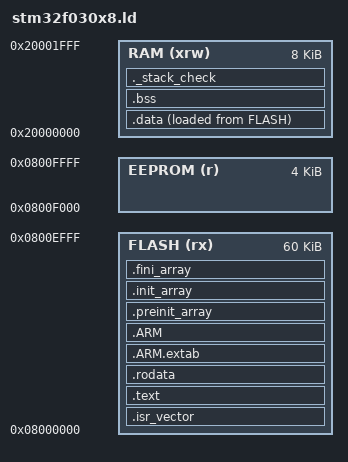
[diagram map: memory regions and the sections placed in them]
/* Linker script for the STM32F030C8 on the BIGTREETECH MMU2-DIP */

ENTRY(Reset_Handler)

/* The last 4 KB of flash hold the emulated EEPROM, see eeprom.cpp */
MEMORY
{
  FLASH (rx)  : ORIGIN = 0x08000000, LENGTH = 60K
  EEPROM (r)  : ORIGIN = 0x0800F000, LENGTH = 4K
  RAM (xrw)   : ORIGIN = 0x20000000, LENGTH = 8K
}

_estack = ORIGIN(RAM) + LENGTH(RAM);
_eeprom_start = ORIGIN(EEPROM);
_eeprom_end = ORIGIN(EEPROM) + LENGTH(EEPROM);

/* Fail the link if this much stack + heap doesn't fit */
_min_stack_size = 0x400;

SECTIONS
{
  .isr_vector :
  {
    . = ALIGN(4);
    KEEP(*(.isr_vector))
    . = ALIGN(4);
  } > FLASH

  .text :
  {
    . = ALIGN(4);
    *(.text)
    *(.text*)
    *(.glue_7)
    *(.glue_7t)
    *(.eh_frame)
    KEEP(*(.init))
    KEEP(*(.fini))
    . = ALIGN(4);
    _etext = .;
  } > FLASH

  .rodata :
  {
    . = ALIGN(4);
    *(.rodata)
    *(.rodata*)
    . = ALIGN(4);
  } > FLASH

  .ARM.extab : { *(.ARM.extab* .gnu.linkonce.armextab.*) } > FLASH
  .ARM : {
    __exidx_start = .;
    *(.ARM.exidx*)
    __exidx_end = .;
  } > FLASH

  .preinit_array :
  {
    PROVIDE_HIDDEN (__preinit_array_start = .);
    KEEP (*(.preinit_array*))
    PROVIDE_HIDDEN (__preinit_array_end = .);
  } > FLASH
  .init_array :
  {
    PROVIDE_HIDDEN (__init_array_start = .);
    KEEP (*(SORT(.init_array.*)))
    KEEP (*(.init_array*))
    PROVIDE_HIDDEN (__init_array_end = .);
  } > FLASH
  .fini_array :
  {
    PROVIDE_HIDDEN (__fini_array_start = .);
    KEEP (*(SORT(.fini_array.*)))
    KEEP (*(.fini_array*))
    PROVIDE_HIDDEN (__fini_array_end = .);
  } > FLASH

  _sidata = LOADADDR(.data);

  .data :
  {
    . = ALIGN(4);
    _sdata = .;
    *(.data)
    *(.data*)
    . = ALIGN(4);
    _edata = .;
  } > RAM AT> FLASH

  .bss (NOLOAD) :
  {
    . = ALIGN(4);
    _sbss = .;
    *(.bss)
    *(.bss*)
    *(COMMON)
    . = ALIGN(4);
    _ebss = .;
    end = .;
    _end = .;
  } > RAM

  ._stack_check (NOLOAD) :
  {
    . = ALIGN(8);
    . = . + _min_stack_size;
    . = ALIGN(8);
  } > RAM

  /DISCARD/ :
  {
    libc.a ( * )
    libm.a ( * )
    libgcc.a ( * )
  }

  .ARM.attributes 0 : { *(.ARM.attributes) }
}
